# MCASP register map
Vendor: Texas Instruments
Peripheral module from a debugger description file (folder am335x).
Registers are 32-bit, read-write, no defined reset value unless marked. A register's access mark holds for its fields unless they carry their own. Offsets are as the file gives them; lines under a group give offsets from that group; [hi:lo] are bit positions; {n}, {i} and the like mark numbered series; 'fields as' and 'values as' point back to an identical list; <NAME> marks a mode.

## McASP
0x00 REV ro — The revision identification register (REV) contains identification data for the peripheral.
  [31:0] REV — Identifies revision of peripheral.
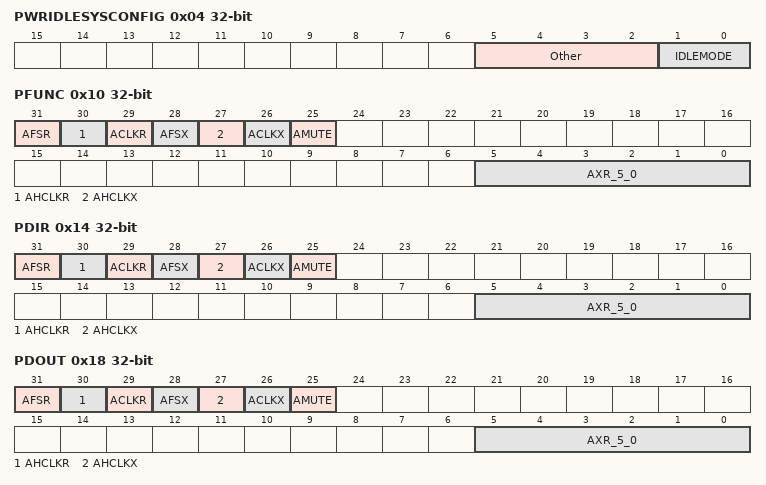
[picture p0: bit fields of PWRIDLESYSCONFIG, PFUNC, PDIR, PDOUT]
0x04 PWRIDLESYSCONFIG access per field
  [5:2] Other rw — Reserved for future programming.
  [1:0] IDLEMODE rw — Power management Configuration of the local target state management mode. By definition, target can handle read/write transaction as long as it is out of IDLE state.
0x10 PFUNC access per field — The pin function register (PFUNC) specifies the function of AXRn, ACLKX, AHCLKX, AFSX, ACLKR, AHCLKR, and AFSR pins as either a McASP pin or a general-purpose input/output (GPIO) pin. CAUTION: Writing a value other than 0 to reserved bits in this register may cause improper device operation.
  [31] AFSR rw — Determines if AFSR pin functions as McASP or GPIO.
  [30] AHCLKR rw — Determines if AHCLKR pin functions as McASP or GPIO.
  [29] ACLKR rw — Determines if ACLKR pin functions as McASP or GPIO.
  [28] AFSX rw — Determines if AFSX pin functions as McASP or GPIO.
  [27] AHCLKX rw — Determines if AHCLKX pin functions as McASP or GPIO.
  [26] ACLKX rw — Determines if ACLKX pin functions as McASP or GPIO.
  [25] AMUTE rw — Determines if AMUTE pin functions as McASP or GPIO.
  [5:0] AXR_5_0 rw — Determines if AXRn pin functions as McASP or GPIO.
0x14 PDIR access per field — The pin direction register (PDIR) specifies the direction of AXRn, ACLKX, AHCLKX, AFSX, ACLKR, AHCLKR, and AFSR pins as either an input or an output pin. Regardless of the pin function register (PFUNC) setting, each PDIR bit must be set to 1 for the specified pin to be enabled as an output and each PDIR bit must be cleared to 0 for the specified pin to be an input. For example, if the McASP is configured to use an internally-generated bit clock and the clock is to be driven out to the system, the PFUNC bit must be cleared to 0 (McASP function) and the PDIR bit must be set to 1 (an output). When AXRn is configured to transmit, the PFUNC bit must be cleared to 0 (McASP function) and the PDIR bit must be set to 1 (an output). Similarly, when AXRn is configured to receive, the PFUNC bit must be cleared to 0 (McASP function) and the PDIR bit must be cleared to 0 (an input). CAUTION: Writing a value other than 0 to reserved bits in this register may cause improper device operation.
  [31] AFSR rw — Determines if AFSR pin functions as an input or output.
  [30] AHCLKR rw — Determines if AHCLKR pin functions as an input or output.
  [29] ACLKR rw — Determines if ACLKR pin functions as an input or output.
  [28] AFSX rw — Determines if AFSX pin functions as an input or output.
  [27] AHCLKX rw — Determines if AHCLKX pin functions as an input or output.
  [26] ACLKX rw — Determines if ACLKX pin functions as an input or output.
  [25] AMUTE rw — Determines if AMUTE pin functions as an input or output.
  [5:0] AXR_5_0 rw — Determines if AXRn pin functions as an input or output.
0x18 PDOUT access per field — The pin data output register (PDOUT) holds a value for data out at all times, and may be read back at all times. The value held by PDOUT is not affected by writing to PDIR and PFUNC. However, the data value in PDOUT is driven out onto the McASP pin only if the corresponding bit in PFUNC is set to 1 (GPIO function) and the corresponding bit in PDIR is set to 1 (output). When reading data, returns the corresponding bit value in PDOUT[n], does not return input from I/O pin; when writing data, writes to the corresponding PDOUT[n] bit. PDOUT has these aliases or alternate addresses: PDSET When written to at this address, writing a 1 to a bit in PDSET sets the corresponding bit in PDOUT to 1; writing a 0 has no effect and keeps the bits in PDOUT unchanged. PDCLR When written to at this address, writing a 1 to a bit in PDCLR clears the corresponding bit in PDOUT to 0; writing a 0 has no effect and keeps the bits in PDOUT unchanged. There is only one set of data out bits, PDOUT[31-0]. The other registers, PDSET and PDCLR, are just different addresses for the same control bits, with different behaviors during writes. CAUTION: Writing a value other than 0 to reserved bits in this register may cause improper device operation.
  [31] AFSR rw — Determines drive on AFSR output pin when the corresponding PFUNC[31] and PDIR[31] bits are set to 1.
  [30] AHCLKR rw — Determines drive on AHCLKR output pin when the corresponding PFUNC[30] and PDIR[30] bits are set to 1.
  [29] ACLKR rw — Determines drive on ACLKR output pin when the corresponding PFUNC[29] and PDIR[29] bits are set to 1.
  [28] AFSX rw — Determines drive on AFSX output pin when the corresponding PFUNC[28] and PDIR[28] bits are set to 1.
  [27] AHCLKX rw — Determines drive on AHCLKX output pin when the corresponding PFUNC[27] and PDIR[27] bits are set to 1.
  [26] ACLKX rw — Determines drive on ACLKX output pin when the corresponding PFUNC[26] and PDIR[26] bits are set to 1.
  [25] AMUTE rw — Determines drive on AMUTE output pin when the corresponding PFUNC[25] and PDIR[25] bits are set to 1.
  [5:0] AXR_5_0 rw — Determines drive on AXR[n] output pin when the corresponding PFUNC[n] and PDIR[n] bits are set to 1.
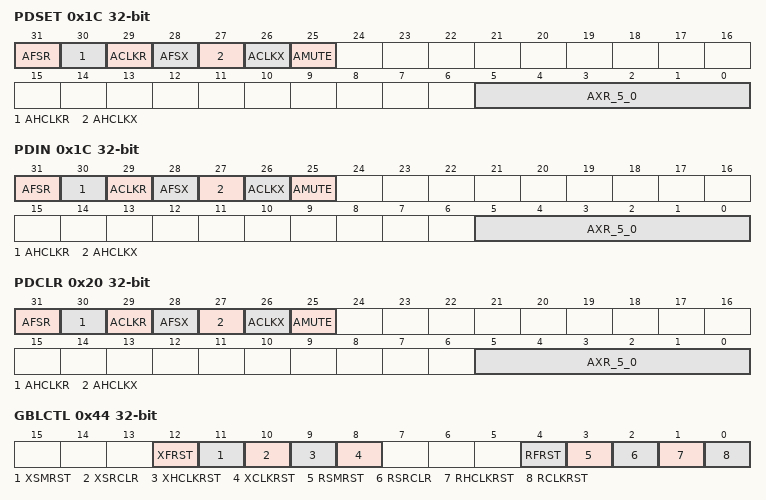
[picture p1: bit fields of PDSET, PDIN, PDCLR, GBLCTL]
0x1C PDSET access per field — The pin data set register (PDSET) is an alias of the pin data output register (PDOUT) for writes only. Writing a 1 to the PDSET bit sets the corresponding bit in PDOUT and, if PFUNC = 1 (GPIO function) and PDIR = 1 (output), drives a logic high on the pin. PDSET is useful for a multitasking system because it allows you to set to a logic high only the desired pin(s) within a system without affecting other I/O pins controlled by the same McASP. CAUTION: Writing a value other than 0 to reserved bits in this register may cause improper device operation.
  [31] AFSR rw — Allows the corresponding AFSR bit in PDOUT to be set to a logic high without affecting other I/O pins controlled by the same port.
  [30] AHCLKR rw — Allows the corresponding AHCLKR bit in PDOUT to be set to a logic high without affecting other I/O pins controlled by the same port.
  [29] ACLKR rw — Allows the corresponding ACLKR bit in PDOUT to be set to a logic high without affecting other I/O pins controlled by the same port.
  [28] AFSX rw — Allows the corresponding AFSX bit in PDOUT to be set to a logic high without affecting other I/O pins controlled by the same port.
  [27] AHCLKX rw — Allows the corresponding AHCLKX bit in PDOUT to be set to a logic high without affecting other I/O pins controlled by the same port.
  [26] ACLKX rw — Allows the corresponding ACLKX bit in PDOUT to be set to a logic high without affecting other I/O pins controlled by the same port.
  [25] AMUTE rw — Allows the corresponding AMUTE bit in PDOUT to be set to a logic high without affecting other I/O pins controlled by the same port.
  [5:0] AXR_5_0 rw — Allows the corresponding AXR[n] bit in PDOUT to be set to a logic high without affecting other I/O pins controlled by the same port.
0x1C PDIN access per field — The pin data input register (PDIN) holds the I/O pin state of each of the McASP pins. PDIN allows the actual value of the pin to be read, regardless of the state of PFUNC and PDIR. The value after reset for registers 1 through 15 and 24 through 31 depends on how the pins are being driven. CAUTION: Writing a value other than 0 to reserved bits in this register may cause improper device operation.
  [31] AFSR rw — Logic level on AFSR pin.
  [30] AHCLKR rw — Logic level on AHCLKR pin.
  [29] ACLKR rw — Logic level on ACLKR pin.
  [28] AFSX rw — Logic level on AFSX pin.
  [27] AHCLKX rw — Logic level on AHCLKX pin.
  [26] ACLKX rw — Logic level on ACLKX pin.
  [25] AMUTE rw — Logic level on AMUTE pin.
  [5:0] AXR_5_0 rw — Logic level on AXR[n] pin.
0x20 PDCLR access per field — The pin data clear register (PDCLR) is an alias of the pin data output register (PDOUT) for writes only. Writing a 1 to the PDCLR bit clears the corresponding bit in PDOUT and, if PFUNC = 1 (GPIO function) and PDIR = 1 (output), drives a logic low on the pin. PDCLR is useful for a multitasking system because it allows you to clear to a logic low only the desired pin(s) within a system without affecting other I/O pins controlled by the same McASP. CAUTION: Writing a value other than 0 to reserved bits in this register may cause improper device operation.
  [31] AFSR rw — Allows the corresponding AFSR bit in PDOUT to be cleared to a logic low without affecting other I/O pins controlled by the same port.
  [30] AHCLKR rw — Allows the corresponding AHCLKR bit in PDOUT to be cleared to a logic low without affecting other I/O pins controlled by the same port.
  [29] ACLKR rw — Allows the corresponding ACLKR bit in PDOUT to be cleared to a logic low without affecting other I/O pins controlled by the same port.
  [28] AFSX rw — Allows the corresponding AFSX bit in PDOUT to be cleared to a logic low without affecting other I/O pins controlled by the same port.
  [27] AHCLKX rw — Allows the corresponding AHCLKX bit in PDOUT to be cleared to a logic low without affecting other I/O pins controlled by the same port.
  [26] ACLKX rw — Allows the corresponding ACLKX bit in PDOUT to be cleared to a logic low without affecting other I/O pins controlled by the same port.
  [25] AMUTE rw — Allows the corresponding AMUTE bit in PDOUT to be cleared to a logic low without affecting other I/O pins controlled by the same port.
  [5:0] AXR_5_0 rw — Allows the corresponding AXR[n] bit in PDOUT to be cleared to a logic low without affecting other I/O pins controlled by the same port.
0x44 GBLCTL access per field — The global control register (GBLCTL) provides initialization of the transmit and receive sections. The bit fields in GBLCTL are synchronized and latched by the corresponding clocks (ACLKX for bits 12-8 and ACLKR for bits 4-0). Before GBLCTL is programmed, you must ensure that serial clocks are running. If the corresponding external serial clocks, ACLKX and ACLKR, are not yet running, you should select the internal serial clock source in AHCLKXCTL, AHCLKRCTL, ACLKXCTL, and ACLKRCTL before GBLCTL is programmed. Also, after programming any bits in GBLCTL you should not proceed until you have read back from GBLCTL and verified that the bits are latched in GBLCTL.
  [12] XFRST rw — Transmit frame sync generator reset enable bit.
  [11] XSMRST rw — Transmit state machine reset enable bit.
  [10] XSRCLR rw — Transmit serializer clear enable bit. By clearing then setting this bit, the transmit buffer is flushed to an empty state (XDATA = 1). If XSMRST = 1, XSRCLR = 1, XDATA = 1, and XBUF is not loaded with new data before the start of the next active time slot, an underrun will occur.
  [9] XHCLKRST rw — Transmit high-frequency clock divider reset enable bit.
  [8] XCLKRST rw — Transmit clock divider reset enable bit.
  [4] RFRST rw — Receive frame sync generator reset enable bit.
  [3] RSMRST rw — Receive state machine reset enable bit.
  [2] RSRCLR rw — Receive serializer clear enable bit. By clearing then setting this bit, the receive buffer is flushed.
  [1] RHCLKRST rw — Receive high-frequency clock divider reset enable bit.
  [0] RCLKRST rw — Receive high-frequency clock divider reset enable bit.
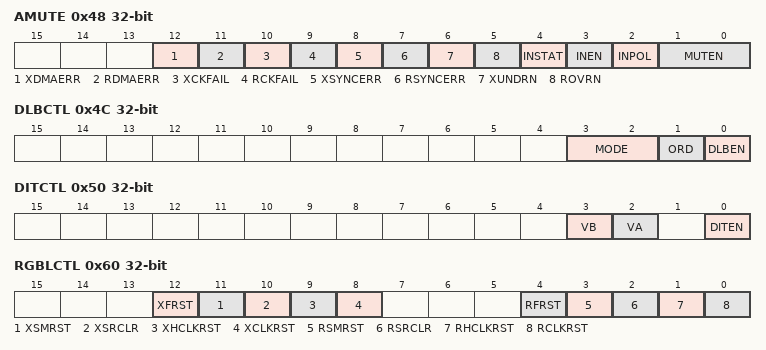
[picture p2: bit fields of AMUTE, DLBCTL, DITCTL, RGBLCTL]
0x48 AMUTE access per field — The audio mute control register (AMUTE) controls the McASP audio mute (AMUTE) output pin. The value after reset for register 4 depends on how the pins are being driven.
  [12] XDMAERR rw — If transmit DMA error (XDMAERR), drive AMUTE active enable bit.
  [11] RDMAERR rw — If receive DMA error (RDMAERR), drive AMUTE active enable bit.
  [10] XCKFAIL rw — If transmit clock failure (XCKFAIL), drive AMUTE active enable bit.
  [9] RCKFAIL rw — If receive clock failure (RCKFAIL), drive AMUTE active enable bit.
  [8] XSYNCERR rw — If unexpected transmit frame sync error (XSYNCERR), drive AMUTE active enable bit.
  [7] RSYNCERR rw — If unexpected receive frame sync error (RSYNCERR), drive AMUTE active enable bit.
  [6] XUNDRN rw — If transmit underrun error (XUNDRN), drive AMUTE active enable bit.
  [5] ROVRN rw — If receiver overrun error (ROVRN), drive AMUTE active enable bit.
  [4] INSTAT ro — Determines drive on AXRn pin when PFUNC[n] and PDIR[n] bits are set to 1.
  [3] INEN rw — Drive AMUTE active when AMUTEIN error is active (INSTAT = 1).
  [2] INPOL rw — Audio mute in (AMUTEIN) polarity select bit.
  [1:0] MUTEN rw — AMUTE pin enable bit (unless overridden by GPIO registers).
0x4C DLBCTL access per field — The digital loopback control register (DLBCTL) controls the internal loopback settings of the McASP in TDM mode.
  [3:2] MODE rw — Loopback generator mode bits. Applies only when loopback mode is enabled (DLBEN = 1).
  [1] ORD rw — Loopback order bit when loopback mode is enabled (DLBEN = 1).
  [0] DLBEN rw — Loopback mode enable bit.
0x50 DITCTL access per field — The DIT mode control register (DITCTL) controls DIT operations of the McASP.
  [3] VB rw — Valid bit for odd time slots (DIT right subframe).
  [2] VA rw — Valid bit for even time slots (DIT left subframe).
  [0] DITEN rw — DIT mode enable bit. DITEN should only be changed while the XSMRST bit in GBLCTL is in reset (and for startup, XSRCLR also in reset). However, it is not necessary to reset the XCLKRST or XHCLKRST bits in GBLCTL to change DITEN.
0x60 RGBLCTL access per field — Alias of the global control register (GBLCTL). Writing to the receiver global control register (RGBLCTL) affects only the receive bits of GBLCTL (bits 4-0). Reads from RGBLCTL return the value of GBLCTL. RGBLCTL allows the receiver to be reset independently from the transmitter.
  [12] XFRST ro — Transmit frame sync generator reset enable bit. A read of this bit returns the XFRST bit value of GBLCTL. Writes have no effect.
  [11] XSMRST ro — Transmit state machine reset enable bit. A read of this bit returns the XSMRST bit value of GBLCTL. Writes have no effect.
  [10] XSRCLR ro — Transmit serializer clear enable bit. A read of this bit returns the XSRCLR bit value of GBLCTL. Writes have no effect.
  [9] XHCLKRST ro — Transmit high-frequency clock divider reset enable bit. A read of this bit returns the XHCLKRST bit value of GBLCTL. Writes have no effect.
  [8] XCLKRST ro — Transmit clock divider reset enable bit. A read of this bit returns the XCLKRST bit value of GBLCTL. Writes have no effect.
  [4] RFRST rw — Receive frame sync generator reset enable bit. A write to this bit affects the RFRST bit of GBLCTL.
  [3] RSMRST rw — Receive state machine reset enable bit. A write to this bit affects the RSMRST bit of GBLCTL.
  [2] RSRCLR rw — Receive serializer clear enable bit. A write to this bit affects the RSRCLR bit of GBLCTL.
  [1] RHCLKRST rw — Receive high-frequency clock divider reset enable bit. A write to this bit affects the RHCLKRST bit of GBLCTL.
  [0] RCLKRST rw — Receive clock divider reset enable bit. A write to this bit affects the RCLKRST bit of GBLCTL.
0x64 RMASK — The receive format unit bit mask register (RMASK) determines which bits of the received data are masked off and padded with a known value before being read by the CPU or DMA.
  [31:0] RMASK_31_0 — Receive data mask n enable bit.
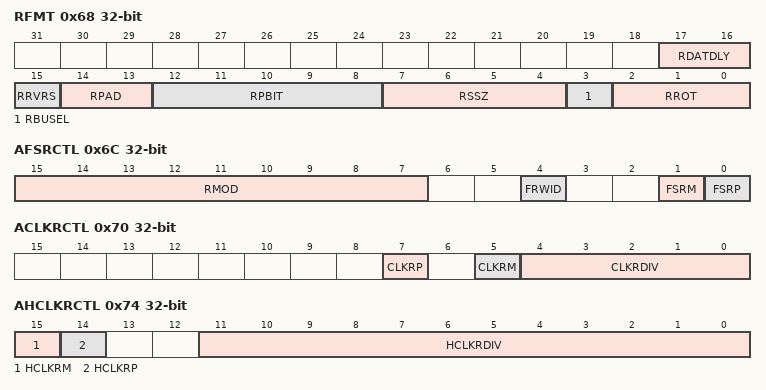
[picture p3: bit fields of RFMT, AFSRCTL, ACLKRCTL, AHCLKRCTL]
0x68 RFMT access per field — The receive bit stream format register (RFMT) configures the receive data format.
  [17:16] RDATDLY rw — Receive bit delay.
  [15] RRVRS rw — Receive serial bitstream order.
  [14:13] RPAD rw — Pad value for extra bits in slot not belonging to the word. This field only applies to bits when RMASK[n] = 0.
  [12:8] RPBIT rw — RPBIT value determines which bit (as read by the CPU or DMA from RBUF[n]) is used to pad the extra bits. This field only applies when RPAD = 2h.
  [7:4] RSSZ rw — Receive slot size.
  [3] RBUSEL rw — Selects whether reads from serializer buffer XRBUF[n] originate from the configuration bus (CFG) or the data (DAT) port.
  [2:0] RROT rw — Right-rotation value for receive rotate right format unit.
0x6C AFSRCTL access per field — The receive frame sync control register (AFSRCTL) configures the receive frame sync (AFSR).
  [15:7] RMOD rw — Receive frame sync mode select bits. 1FFh = Reserved from 181h to 1FFh.
  [4] FRWID rw — Receive frame sync width select bit indicates the width of the receive frame sync (AFSR) during its active period.
  [1] FSRM rw — Receive frame sync generation select bit.
  [0] FSRP rw — Receive frame sync polarity select bit.
0x70 ACLKRCTL access per field — The receive clock control register (ACLKRCTL) configures the receive bit clock (ACLKR) and the receive clock generator.
  [7] CLKRP rw — Receive bitstream clock polarity select bit.
  [5] CLKRM rw — Receive bit clock source bit. Note that this bit does not have any effect, if ACLKXCTL.ASYNC = 0.
  [4:0] CLKRDIV rw — Receive bit clock divide ratio bits determine the divide-down ratio from AHCLKR to ACLKR. Note that this bit does not have any effect, if ACLKXCTL.ASYNC = 0.
0x74 AHCLKRCTL access per field — The receive high-frequency clock control register (AHCLKRCTL) configures the receive high-frequency master clock (AHCLKR) and the receive clock generator.
  [15] HCLKRM rw — Receive high-frequency clock source bit.
  [14] HCLKRP rw — Receive bitstream high-frequency clock polarity select bit.
  [11:0] HCLKRDIV rw — Receive high-frequency clock divide ratio bits determine the divide-down ratio from AUXCLK to AHCLKR.
0x78 RTDM — The receive TDM time slot register (RTDM) specifies which TDM time slot the receiver is active.
  [31:0] RTDMS_31_0 — Receiver mode during TDM time slot n.
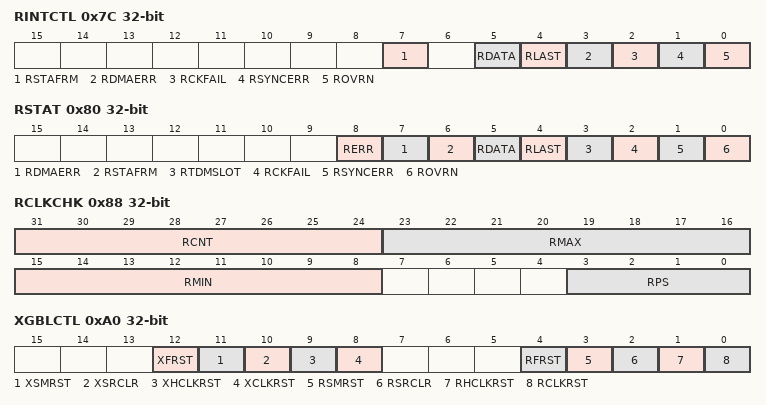
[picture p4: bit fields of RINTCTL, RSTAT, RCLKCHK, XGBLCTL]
0x7C RINTCTL access per field — The receiver interrupt control register (RINTCTL) controls generation of the McASP receive interrupt (RINT). When the register bit(s) is set to 1, the occurrence of the enabled McASP condition(s) generates RINT. See the RSTAT register for a description of the interrupt conditions.
  [7] RSTAFRM rw — Receive start of frame interrupt enable bit.
  [5] RDATA rw — Receive data ready interrupt enable bit.
  [4] RLAST rw — Receive last slot interrupt enable bit.
  [3] RDMAERR rw — Receive DMA error interrupt enable bit.
  [2] RCKFAIL rw — Receive clock failure interrupt enable bit.
  [1] RSYNCERR rw — Unexpected receive frame sync interrupt enable bit.
  [0] ROVRN rw — Receiver overrun interrupt enable bit.
0x80 RSTAT access not given — The receiver status register (RSTAT) provides the receiver status and receive TDM time slot number. If the McASP logic attempts to set an interrupt flag in the same cycle that the CPU writes to the flag to clear it, the McASP logic has priority and the flag remains set. This also causes a new interrupt request to be generated.
  [8] RERR rw — RERR bit always returns a logic-OR of: ROVRN OR RSYNCERR OR RCKFAIL OR RDMAERR. Allows a single bit to be checked to determine if a receiver error interrupt has occurred.
  [7] RDMAERR — Receive DMA error flag. RDMAERR is set when the CPU or DMA reads more serializers through the data port in a given time slot than were programmed as receivers. Causes a receive interrupt (RINT), if this bit is set and RDMAERR in RINTCTL is set. This bit is cleared by writing a 1 to this bit. Writing a 0 to this bit has no effect. (access R/W1C)
  [6] RSTAFRM — Receive start of frame flag. Causes a receive interrupt (RINT), if this bit is set and RSTAFRM in RINTCTL is set. This bit is cleared by writing a 1 to this bit. Writing a 0 to this bit has no effect. (access R/W1C)
  [5] RDATA — Receive data ready flag. Causes a receive interrupt (RINT), if this bit is set and RDATA in RINTCTL is set. This bit is cleared by writing a 1 to this bit. Writing a 0 to this bit has no effect. (access R/W1C)
  [4] RLAST — Receive last slot flag. RLAST is set along with RDATA, if the current slot is the last slot in a frame. Causes a receive interrupt (RINT), if this bit is set and RLAST in RINTCTL is set. This bit is cleared by writing a 1 to this bit. Writing a 0 to this bit has no effect. (access R/W1C)
  [3] RTDMSLOT ro — Returns the LSB of RSLOT. Allows a single read of RSTAT to determine whether the current TDM time slot is even or odd.
  [2] RCKFAIL — Receive clock failure flag. RCKFAIL is set when the receive clock failure detection circuit reports an error. Causes a receive interrupt (RINT), if this bit is set and RCKFAIL in RINTCTL is set. This bit is cleared by writing a 1 to this bit. Writing a 0 to this bit has no effect. (access R/W1C)
  [1] RSYNCERR — Unexpected receive frame sync flag. RSYNCERR is set when a new receive frame sync (AFSR) occurs before it is expected. Causes a receive interrupt (RINT), if this bit is set and RSYNCERR in RINTCTL is set. This bit is cleared by writing a 1 to this bit. Writing a 0 to this bit has no effect. (access R/W1C)
  [0] ROVRN — Receiver overrun flag. ROVRN is set when the receive serializer is instructed to transfer data from XRSR to RBUF, but the former data in RBUF has not yet been read by the CPU or DMA. Causes a receive interrupt (RINT), if this bit is set and ROVRN in RINTCTL is set. This bit is cleared by writing a 1 to this bit. Writing a 0 to this bit has no effect. (access R/W1C)
0x84 RSLOT ro — The current receive TDM time slot register (RSLOT) indicates the current time slot for the receive data frame.
  [8:0] RSLOTCNT — 0-17Fh = Current receive time slot count. Legal values: 0 to 383 (17Fh). TDM function is not supported for > 32 time slots. However, TDM time slot counter may count to 383 when used to receive a DIR block (transferred over TDM format).
0x88 RCLKCHK access per field — The receive clock check control register (RCLKCHK) configures the receive clock failure detection circuit.
  [31:24] RCNT ro — Receive clock count value (from previous measurement). The clock circuit continually counts the number of system clocks for every 32 receive high-frequency master clock (AHCLKR) signals, and stores the count in RCNT until the next measurement is taken.
  [23:16] RMAX rw — Receive clock maximum boundary. This 8 bit unsigned value sets the maximum allowed boundary for the clock check counter after 32 receive high-frequency master clock (AHCLKR) signals have been received. If the current counter value is greater than RMAX after counting 32 AHCLKR signals, RCKFAIL in RSTAT is set. The comparison is performed using unsigned arithmetic.
  [15:8] RMIN rw — Receive clock minimum boundary. This 8 bit unsigned value sets the minimum allowed boundary for the clock check counter after 32 receive high-frequency master clock (AHCLKR) signals have been received. If RCNT is less than RMIN after counting 32 AHCLKR signals, RCKFAIL in RSTAT is set. The comparison is performed using unsigned arithmetic.
  [3:0] RPS rw — Receive clock check prescaler value.
0x8C REVTCTL access per field — The receiver DMA event control register (REVTCTL) contains a disable bit for the receiver DMA event. Note for device-specific registers: Accessing REVTCTL not implemented on a specific device may cause improper operation.
  [0] RDATDMA rw — Receive data DMA request enable bit. If writing to this bit, always write the default value of 0.
0xA0 XGBLCTL access per field — Alias of the global control register (GBLCTL). Writing to the transmitter global control register (XGBLCTL) affects only the transmit bits of GBLCTL (bits 12-8). Reads from XGBLCTL return the value of GBLCTL. XGBLCTL allows the transmitter to be reset independently from the receiver. See the GBLCTL register for a detailed description of GBLCTL.
  [12] XFRST rw — Transmit frame sync generator reset enable bit. A write to this bit affects the XFRST bit of GBLCTL.
  [11] XSMRST rw — Transmit state machine reset enable bit. A write to this bit affects the XSMRST bit of GBLCTL.
  [10] XSRCLR rw — Transmit serializer clear enable bit. A write to this bit affects the XSRCLR bit of GBLCTL.
  [9] XHCLKRST rw — Transmit high-frequency clock divider reset enable bit. A write to this bit affects the XHCLKRST bit of GBLCTL.
  [8] XCLKRST rw — Transmit clock divider reset enable bit. A write to this bit affects the XCLKRST bit of GBLCTL.
  [4] RFRST ro — Receive frame sync generator reset enable bit. A read of this bit returns the RFRST bit value of GBLCTL. Writes have no effect.
  [3] RSMRST ro — Receive state machine reset enable bit. A read of this bit returns the RSMRST bit value of GBLCTL. Writes have no effect.
  [2] RSRCLR ro — Receive serializer clear enable bit. A read of this bit returns the RSRSCLR bit value of GBLCTL. Writes have no effect.
  [1] RHCLKRST ro — Receive high-frequency clock divider reset enable bit. A read of this bit returns the RHCLKRST bit value of GBLCTL. Writes have no effect.
  [0] RCLKRST ro — Receive clock divider reset enable bit. A read of this bit returns the RCLKRST bit value of GBLCTL. Writes have no effect.
0xA4 XMASK — The transmit format unit bit mask register (XMASK) determines which bits of the transmitted data are masked off and padded with a known value before being shifted out the McASP.
  [31:0] XMASK_31_0 — Transmit data mask n enable bit.
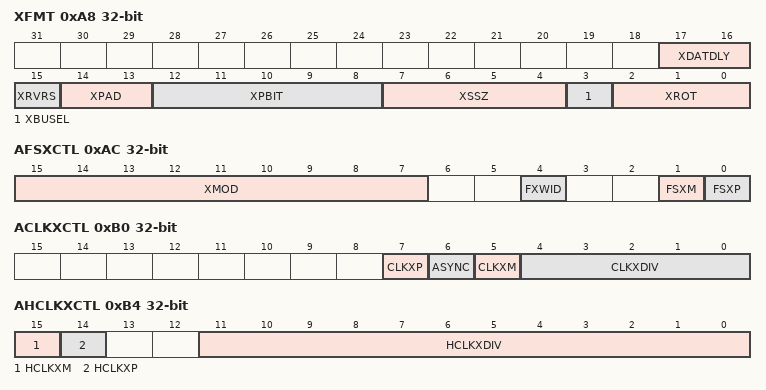
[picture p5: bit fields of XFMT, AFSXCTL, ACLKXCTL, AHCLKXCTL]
0xA8 XFMT access per field — The transmit bit stream format register (XFMT) configures the transmit data format.
  [17:16] XDATDLY rw — Transmit sync bit delay.
  [15] XRVRS rw — Transmit serial bitstream order.
  [14:13] XPAD rw — Pad value for extra bits in slot not belonging to word defined by XMASK. This field only applies to bits when XMASK[n] = 0.
  [12:8] XPBIT rw — XPBIT value determines which bit (as written by the CPU or DMA to XBUF[n]) is used to pad the extra bits before shifting. This field only applies when XPAD = 2h.
  [7:4] XSSZ rw — Transmit slot size.
  [3] XBUSEL rw — Selects whether writes to serializer buffer XRBUF[n] originate from the configuration bus (CFG) or the data (DAT) port.
  [2:0] XROT rw — Right-rotation value for transmit rotate right format unit.
0xAC AFSXCTL access per field — The transmit frame sync control register (AFSXCTL) configures the transmit frame sync (AFSX).
  [15:7] XMOD rw — Transmit frame sync mode select bits. 1FFh = Reserved from 181h to 1FFh.
  [4] FXWID rw — Transmit frame sync width select bit indicates the width of the transmit frame sync (AFSX) during its active period.
  [1] FSXM rw — Transmit frame sync generation select bit.
  [0] FSXP rw — Transmit frame sync polarity select bit.
0xB0 ACLKXCTL access per field — The transmit clock control register (ACLKXCTL) configures the transmit bit clock (ACLKX) and the transmit clock generator.
  [7] CLKXP rw — Transmit bitstream clock polarity select bit.
  [6] ASYNC rw — Transmit/receive operation asynchronous enable bit.
  [5] CLKXM rw — Transmit bit clock source bit.
  [4:0] CLKXDIV rw — Transmit bit clock divide ratio bits determine the divide-down ratio from AHCLKX to ACLKX.
0xB4 AHCLKXCTL access per field — The transmit high-frequency clock control register (AHCLKXCTL) configures the transmit high-frequency master clock (AHCLKX) and the transmit clock generator.
  [15] HCLKXM rw — Transmit high-frequency clock source bit.
  [14] HCLKXP rw — Transmit bitstream high-frequency clock polarity select bit.
  [11:0] HCLKXDIV rw — Transmit high-frequency clock divide ratio bits determine the divide-down ratio from AUXCLK to AHCLKX.
0xB8 XTDM — The transmit TDM time slot register (XTDM) specifies in which TDM time slot the transmitter is active. TDM time slot counter range is extended to 384 slots (to support SPDIF blocks of 384 subframes). XTDM operates modulo 32, that is, XTDMS specifies the TDM activity for time slots 0, 32, 64, 96, 128, and so on.
  [31:0] XTDMS_31_0 — Transmitter mode during TDM time slot n.
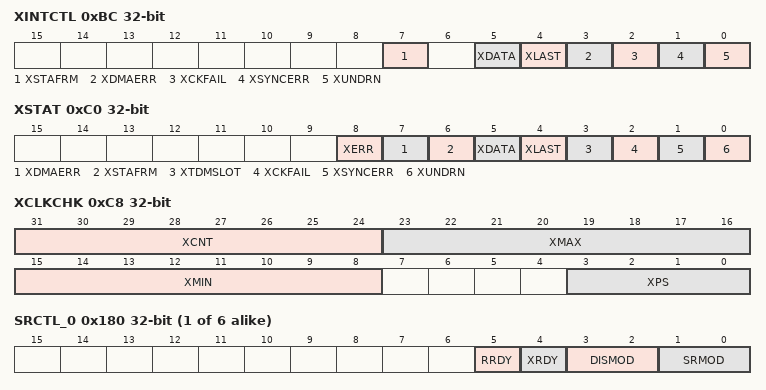
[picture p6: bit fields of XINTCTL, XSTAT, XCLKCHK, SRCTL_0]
0xBC XINTCTL access per field — The transmitter interrupt control register (XINTCTL) controls generation of the McASP transmit interrupt (XINT). When the register bit(s) is set to 1, the occurrence of the enabled McASP condition(s) generates XINT. See the XSTAT register for a description of the interrupt conditions.
  [7] XSTAFRM rw — Transmit start of frame interrupt enable bit.
  [5] XDATA rw — Transmit data ready interrupt enable bit.
  [4] XLAST rw — Transmit last slot interrupt enable bit.
  [3] XDMAERR rw — Transmit DMA error interrupt enable bit.
  [2] XCKFAIL rw — Transmit clock failure interrupt enable bit.
  [1] XSYNCERR rw — Unexpected transmit frame sync interrupt enable bit.
  [0] XUNDRN rw — Transmitter underrun interrupt enable bit.
0xC0 XSTAT access not given — The transmitter status register (XSTAT) provides the transmitter status and transmit TDM time slot number. If the McASP logic attempts to set an interrupt flag in the same cycle that the CPU writes to the flag to clear it, the McASP logic has priority and the flag remains set. This also causes a new interrupt request to be generated.
  [8] XERR rw — XERR bit always returns a logic-OR of: XUNDRN OR XSYNCERR OR XCKFAIL OR XDMAERR. Allows a single bit to be checked to determine if a transmitter error interrupt has occurred.
  [7] XDMAERR — Transmit DMA error flag. XDMAERR is set when the CPU or DMA writes more serializers through the data port in a given time slot than were programmed as transmitters. Causes a transmit interrupt (XINT), if this bit is set and XDMAERR in XINTCTL is set. This bit is cleared by writing a 1 to this bit. Writing a 0 has no effect. (access R/W1C)
  [6] XSTAFRM — Transmit start of frame flag. Causes a transmit interrupt (XINT), if this bit is set and XSTAFRM in XINTCTL is set. This bit is cleared by writing a 1 to this bit. Writing a 0 has no effect. (access R/W1C)
  [5] XDATA — Transmit data ready flag. Causes a transmit interrupt (XINT), if this bit is set and XDATA in XINTCTL is set. This bit is cleared by writing a 1 to this bit. Writing a 0 has no effect. (access R/W1C)
  [4] XLAST — Transmit last slot flag. XLAST is set along with XDATA, if the current slot is the last slot in a frame. Causes a transmit interrupt (XINT), if this bit is set and XLAST in XINTCTL is set. This bit is cleared by writing a 1 to this bit. Writing a 0 has no effect. (access R/W1C)
  [3] XTDMSLOT ro — Returns the LSB of XSLOT. Allows a single read of XSTAT to determine whether the current TDM time slot is even or odd.
  [2] XCKFAIL — Transmit clock failure flag. XCKFAIL is set when the transmit clock failure detection circuit reports an error. Causes a transmit interrupt (XINT), if this bit is set and XCKFAIL in XINTCTL is set. This bit is cleared by writing a 1 to this bit. Writing a 0 has no effect. (access R/W1C)
  [1] XSYNCERR — Unexpected transmit frame sync flag. XSYNCERR is set when a new transmit frame sync (AFSX) occurs before it is expected. Causes a transmit interrupt (XINT), if this bit is set and XSYNCERR in XINTCTL is set. This bit is cleared by writing a 1 to this bit. Writing a 0 has no effect. (access R/W1C)
  [0] XUNDRN — Transmitter underrun flag. XUNDRN is set when the transmit serializer is instructed to transfer data from XBUF to XRSR, but XBUF has not yet been serviced with new data since the last transfer. Causes a transmit interrupt (XINT), if this bit is set and XUNDRN in XINTCTL is set. This bit is cleared by writing a 1 to this bit. Writing a 0 has no effect. (access R/W1C)
0xC4 XSLOT ro — The current transmit TDM time slot register (XSLOT) indicates the current time slot for the transmit data frame.
  [9:0] XSLOTCNT — Current transmit time slot count. Legal values: 0 to 383 (17Fh). During reset, this counter value is 383 so the next count value, which is used to encode the first DIT group of data, will be 0 and encodes the B preamble. TDM function is not supported for >32 time slots. However, TDM time slot counter may count to 383 when used to transmit a DIT block.
0xC8 XCLKCHK access per field — The transmit clock check control register (XCLKCHK) configures the transmit clock failure detection circuit.
  [31:24] XCNT ro — Transmit clock count value (from previous measurement). The clock circuit continually counts the number of system clocks for every 32 transmit high-frequency master clock (AHCLKX) signals, and stores the count in XCNT until the next measurement is taken.
  [23:16] XMAX rw — Transmit clock maximum boundary. This 8 bit unsigned value sets the maximum allowed boundary for the clock check counter after 32 transmit high-frequency master clock (AHCLKX) signals have been received. If the current counter value is greater than XMAX after counting 32 AHCLKX signals, XCKFAIL in XSTAT is set. The comparison is performed using unsigned arithmetic.
  [15:8] XMIN rw — Transmit clock minimum boundary. This 8 bit unsigned value sets the minimum allowed boundary for the clock check counter after 32 transmit high-frequency master clock (AHCLKX) signals have been received. If XCNT is less than XMIN after counting 32 AHCLKX signals, XCKFAIL in XSTAT is set. The comparison is performed using unsigned arithmetic.
  [3:0] XPS rw — Transmit clock check prescaler value. Fh = Reserved from 9h to Fh.
0xCC XEVTCTL access per field — The transmitter DMA event control register (XEVTCTL) contains a disable bit for the transmit DMA event. Note for device-specific registers: Accessing XEVTCTL not implemented on a specific device may cause improper device operation.
  [0] XDATDMA rw — Transmit data DMA request enable bit. If writing to this bit, always write the default value of 0.
{0x100+4i} DITCSRA_{i} (i=0..5) — The DIT left channel status registers (DITCSRA) provide the status of each left channel (even TDM time slot). Each of the six 32-bit registers ( ) can store 192 bits of channel status data for a complete block of transmission. The DIT reuses the same data for the next block. It is your responsibility to update the register file in time, if a different set of data need to be sent.
  [31:0] DITCSRA_n — DIT left channel status registers.
{0x118+4i} DITCSRB_{i} (i=0..5) — The DIT right channel status registers (DITCSRB) provide the status of each right channel (odd TDM time slot). Each of the six 32-bit registers ( ) can store 192 bits of channel status data for a complete block of transmission. The DIT reuses the same data for the next block. It is your responsibility to update the register file in time, if a different set of data need to be sent.
  [31:0] DITCSRB_n — DIT right channel status registers.
{0x130+4i} DITUDRA_{i} (i=0..5) — The DIT left channel user data registers (DITUDRA) provides the user data of each left channel (even TDM time slot). Each of the six 32-bit registers ( ) can store 192 bits of user data for a complete block of transmission. The DIT reuses the same data for the next block. It is your responsibility to update the register in time, if a different set of data need to be sent.
  [31:0] DITUDRA_n — DIT left channel user data registers.
{0x148+4i} DITUDRB_{i} (i=0..5) — The DIT right channel user data registers (DITUDRB) provides the user data of each right channel (odd TDM time slot). Each of the six 32-bit registers ( ) can store 192 bits of user data for a complete block of transmission. The DIT reuses the same data for the next block. It is your responsibility to update the register in time, if a different set of data need to be sent.
  [31:0] DITUDRB_n — DIT right channel user data registers.
{0x180+4i} SRCTL_{i} access per field (i=0..5) — Each serializer on the McASP has a serializer control register (SRCTL). There are up to 16 serializers per McASP. Note for device-specific registers: Accessing SRCTLn not implemented on a specific device may cause improper device operation.
  [5] RRDY ro — Receive buffer ready bit. RRDY indicates the current receive buffer state. Always reads 0 when programmed as a transmitter or as inactive. If SRMOD bit is set to receive (2h), RRDY switches from 0 to 1 whenever data is transferred from XRSR to RBUF.
  [4] XRDY ro — Transmit buffer ready bit. XRDY indicates the current transmit buffer state. Always reads 0 when programmed as a receiver or as inactive. If SRMOD bit is set to transmit (1h), XRDY switches from 0 to 1 when XSRCLR in GBLCTL is switched from 0 to 1 to indicate an empty transmitter. XRDY remains set until XSRCLR is forced to 0, data is written to the corresponding transmit buffer, or SRMOD bit is changed to receive (2h) or inactive (0).
  [3:2] DISMOD rw — Serializer pin drive mode bit. Drive on pin when in inactive TDM slot of transmit mode or when serializer is inactive. This field only applies if the pin is configured as a McASP pin (PFUNC = 0).
  [1:0] SRMOD rw — Serializer mode bit.
{0x200+4i} XBUF_{i} (i=0..5) — The transmit buffers for the serializers (XBUF) hold data from the transmit format unit. For transmit operations, the XBUF ( ) is an alias of the XRBUF in the serializer. Accessing XBUF registers not implemented on a specific device may cause improper device operation.
  [31:0] XBUF_n — Transmit buffers for serializers.
{0x280+4i} RBUF_{i} (i=0..5) — The receive buffers for the serializers (RBUF) hold data from the serializer before the data goes to the receive format unit. For receive operations, the RBUF ( ) is an alias of the XRBUF in the serializer. Accessing XBUF registers not implemented on a specific device may cause improper device operation.
  [31:0] RBUF_n — Receive buffers for serializers.
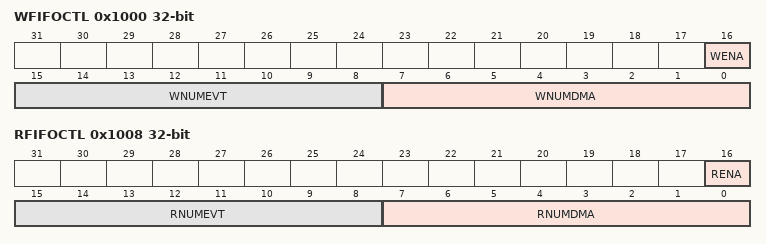
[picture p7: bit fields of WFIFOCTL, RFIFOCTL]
0x1000 WFIFOCTL access per field — The WNUMEVT and WNUMDMA values must be set prior to enabling the Write FIFO. If the Write FIFO is to be enabled, it must be enabled prior to taking the McASP out of reset
  [16] WENA rw — Write FIFO enable bit.
  [15:8] WNUMEVT rw — Write word count per DMA event (32 bit). When the Write FIFO has space for at least WNUMEVT words of data, then an AXEVT (transmit DMA event) is generated to the host/DMA controller. This value should be set to a non-zero integer multiple of the number of serializers enabled as transmitters. This value must be set prior to enabling the Write FIFO. 40h = 3 to 64 words from 3h to 40h. FFh = Reserved from 41h to FFh.
  [7:0] WNUMDMA rw — Write word count per transfer (32 bit words). Upon a transmit DMA event from the McASP, WNUMDMA words are transferred from the Write FIFO to the McASP. This value must equal the number of McASP serializers used as transmitters. This value must be set prior to enabling the Write FIFO. FFh = Reserved from 11h to FFh.
0x1004 WFIFOSTS ro
  [7:0] WLVL — Write level (read-only). Number of 32 bit words currently in the Write FIFO. 40h = 3 to 64 words currently in Write FIFO from 3h to 40h. FFh = Reserved from 41h to FFh.
0x1008 RFIFOCTL access per field — The RNUMEVT and RNUMDMA values must be set prior to enabling the Read FIFO. If the Read FIFO is to be enabled, it must be enabled prior to taking the McASP out of reset
  [16] RENA rw — Read FIFO enable bit.
  [15:8] RNUMEVT rw — Read word count per DMA event (32 bit). When the Read FIFO contains at least RNUMEVT words of data, then an AREVT (receive DMA event) is generated to the host/DMA controller. This value should be set to a non-zero integer multiple of the number of serializers enabled as receivers. This value must be set prior to enabling the Read FIFO. 40h = 3 to 64 words from 3h to 40h. FFh = Reserved from 41h = FFh.
  [7:0] RNUMDMA rw — Read word count per transfer (32 bit words). Upon a receive DMA event from the McASP, the Read FIFO reads RNUMDMA words from the McASP. This value must equal the number of McASP serializers used as receivers. This value must be set prior to enabling the Read FIFO. 10h = 3 to 16 words from 3h to 10h. FFh = Reserved from 11h to FFh.
0x100C RFIFOSTS ro
  [7:0] RLVL — Read level (read-only). Number of 32 bit words currently in the Read FIFO. 40h = 3 to 64 words currently in Read FIFO from 3h to 40h. FFh = Reserved from 41h to FFh.
